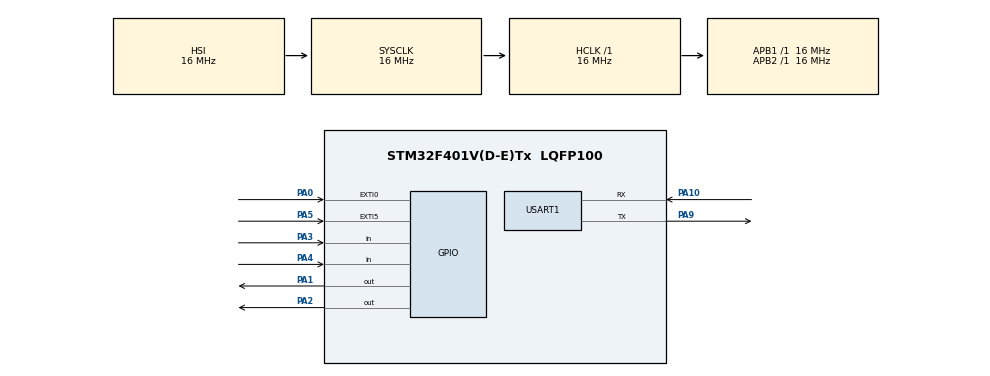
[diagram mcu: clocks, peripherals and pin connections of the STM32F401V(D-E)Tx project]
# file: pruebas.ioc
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Mcu.Family=STM32F4
Mcu.Name=STM32F401V(D-E)Tx
Mcu.Package=LQFP100
NVIC.EXTI0_IRQn=true\:0\:0\:false\:false\:true\:true\:true
NVIC.EXTI9_5_IRQn=true\:0\:0\:false\:false\:true\:true\:true
NVIC.PriorityGroup=NVIC_PRIORITYGROUP_4
NVIC.USART1_IRQn=true\:0\:0\:false\:false\:true\:true\:true
PA0-WKUP.Signal=GPXTI0
PA1.GPIO_Speed=GPIO_SPEED_FREQ_HIGH
PA1.Signal=GPIO_Output
PA10.Mode=Asynchronous
PA10.Signal=USART1_RX
PA2.GPIO_Speed=GPIO_SPEED_FREQ_MEDIUM
PA2.Signal=GPIO_Output
PA3.GPIO_PuPd=GPIO_PULLDOWN
PA3.Signal=GPIO_Input
PA4.GPIO_PuPd=GPIO_NOPULL
PA4.Signal=GPIO_Input
PA5.Signal=GPXTI5
PA9.Mode=Asynchronous
PA9.Signal=USART1_TX
ProjectManager.HeapSize=0x200
ProjectManager.StackSize=0x400
ProjectManager.TargetToolchain=STM32CubeIDE
RCC.AHBFreq_Value=16000000
RCC.APB1Freq_Value=16000000
RCC.APB2Freq_Value=16000000
RCC.CortexFreq_Value=16000000
RCC.HSE_VALUE=25000000
RCC.HSI_VALUE=16000000
RCC.LSE_VALUE=32768
RCC.SYSCLKFreq_VALUE=16000000
RCC.VCOOutputFreq_Value=192000000
USART1.VirtualMode=VM_ASYNC
board=custom

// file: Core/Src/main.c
#include "main.h"

#ifdef __GNUC__
#define PUTCHAR_PROTOTYPE int __io_putchar(int ch)
#else
#define PUTCHAR_PROTOTYPE int fputc(int ch, FILE *f)
#endif /*__GNUC__*/

#define BOTON GPIO_PIN_1
#define LED1 GPIO_PIN_2
#define LED2 GPIO_PIN_3
#define LED3 GPIO_PIN_4

UART_HandleTypeDef huart1;

void SystemClock_Config(void);
static void MX_GPIO_Init(void);
static void MX_USART1_UART_Init(void);
/* USER CODE BEGIN PFP */

int main(void)
{
   /* Reset of all peripherals, Initializes the Flash interface and the Systick. */
  HAL_Init();

   /* Configure the system clock */
  SystemClock_Config();

  /* Initialize all configured peripherals */
  MX_GPIO_Init();
  MX_USART1_UART_Init();
  /* USER CODE BEGIN 2 */

  char mistring[] = "**Test finished successfully. **\n\r";

    //printf("\n\r UART Printf Example: retarget the C library printf function to the UART\n\r");
    //printf("**Test finished successfully. **\n\r");
  /* USER CODE END 2 */

  /* Infinite loop */
  while (1)
  {
	  //printf("**Test finished successfully. **\n\r");
	  	  HAL_GPIO_TogglePin(GPIOA, LED1);
	  	  //HAL_GPIO_WritePin(GPIOA, GPIO_PIN_2, 1);
	  	HAL_UART_Transmit(&huart1, (uint8_t *)mistring, sizeof(mistring)/sizeof(char), 0xFFF);
	  	  HAL_Delay(500);
  }
}

void SystemClock_Config(void)
{
  RCC_OscInitTypeDef RCC_OscInitStruct = {0};
  RCC_ClkInitTypeDef RCC_ClkInitStruct = {0};

  /** Configure the main internal regulator output voltage
  */
  __HAL_RCC_PWR_CLK_ENABLE();
  __HAL_PWR_VOLTAGESCALING_CONFIG(PWR_REGULATOR_VOLTAGE_SCALE2);
  /** Initializes the RCC Oscillators according to the specified parameters
  * in the RCC_OscInitTypeDef structure.
  */
  RCC_OscInitStruct.OscillatorType = RCC_OSCILLATORTYPE_HSI;
  RCC_OscInitStruct.HSIState = RCC_HSI_ON;
  RCC_OscInitStruct.HSICalibrationValue = RCC_HSICALIBRATION_DEFAULT;
  RCC_OscInitStruct.PLL.PLLState = RCC_PLL_NONE;
  if (HAL_RCC_OscConfig(&RCC_OscInitStruct) != HAL_OK)
  {
    Error_Handler();
  }
  /** Initializes the CPU, AHB and APB buses clocks
  */
  RCC_ClkInitStruct.ClockType = RCC_CLOCKTYPE_HCLK|RCC_CLOCKTYPE_SYSCLK
                              |RCC_CLOCKTYPE_PCLK1|RCC_CLOCKTYPE_PCLK2;
  RCC_ClkInitStruct.SYSCLKSource = RCC_SYSCLKSOURCE_HSI;
  RCC_ClkInitStruct.AHBCLKDivider = RCC_SYSCLK_DIV1;
  RCC_ClkInitStruct.APB1CLKDivider = RCC_HCLK_DIV1;
  RCC_ClkInitStruct.APB2CLKDivider = RCC_HCLK_DIV1;

  if (HAL_RCC_ClockConfig(&RCC_ClkInitStruct, FLASH_LATENCY_0) != HAL_OK)
  {
    Error_Handler();
  }
}

static void MX_USART1_UART_Init(void)
{

  huart1.Instance = USART1;
  huart1.Init.BaudRate = 9600;
  huart1.Init.WordLength = UART_WORDLENGTH_8B;
  huart1.Init.StopBits = UART_STOPBITS_1;
  huart1.Init.Parity = UART_PARITY_ODD;
  huart1.Init.Mode = UART_MODE_TX_RX;
  huart1.Init.HwFlowCtl = UART_HWCONTROL_NONE;
  huart1.Init.OverSampling = UART_OVERSAMPLING_16;
  if (HAL_UART_Init(&huart1) != HAL_OK)
  {
    Error_Handler();
  }

}

static void MX_GPIO_Init(void)
{
  GPIO_InitTypeDef GPIO_InitStruct = {0};

  /* GPIO Ports Clock Enable */
  __HAL_RCC_GPIOA_CLK_ENABLE();

  /*Configure GPIO pin Output Level */
  HAL_GPIO_WritePin(GPIOA, GPIO_PIN_1|GPIO_PIN_2, GPIO_PIN_RESET);

  /*Configure GPIO pins : PA0 PA5 */
  GPIO_InitStruct.Pin = GPIO_PIN_0|GPIO_PIN_5;
  GPIO_InitStruct.Mode = GPIO_MODE_IT_RISING;
  GPIO_InitStruct.Pull = GPIO_NOPULL;
  HAL_GPIO_Init(GPIOA, &GPIO_InitStruct);

  /*Configure GPIO pin : PA1 */
    GPIO_InitStruct.Pin = GPIO_PIN_1;
    GPIO_InitStruct.Mode = GPIO_MODE_INPUT;
    GPIO_InitStruct.Pull = GPIO_NOPULL;
    HAL_GPIO_Init(GPIOA, &GPIO_InitStruct);

  /*Configure GPIO pins : PA2 PA3 PA4 */
    GPIO_InitStruct.Pin = GPIO_PIN_2|GPIO_PIN_3|GPIO_PIN_4;
    GPIO_InitStruct.Mode = GPIO_MODE_OUTPUT_PP;
    GPIO_InitStruct.Pull = GPIO_NOPULL;
    GPIO_InitStruct.Speed = GPIO_SPEED_FREQ_HIGH;
    HAL_GPIO_Init(GPIOA, &GPIO_InitStruct);

  /* EXTI interrupt init*/
  HAL_NVIC_SetPriority(EXTI0_IRQn, 0, 0);
  HAL_NVIC_EnableIRQ(EXTI0_IRQn);

  HAL_NVIC_SetPriority(EXTI9_5_IRQn, 0, 0);
  HAL_NVIC_EnableIRQ(EXTI9_5_IRQn);

}

void Error_Handler(void)
{
  /* USER CODE BEGIN Error_Handler_Debug */
  /* User can add his own implementation to report the HAL error return state */
  __disable_irq();
  while (1)
  {
	  HAL_GPIO_TogglePin(GPIOA, LED1);
	  //HAL_GPIO_WritePin(GPIOA, GPIO_PIN_2, 1);
	  HAL_Delay(500);
  }
  /* USER CODE END Error_Handler_Debug */
}

/************************ (C) COPYRIGHT STMicroelectronics *****END OF FILE****/
